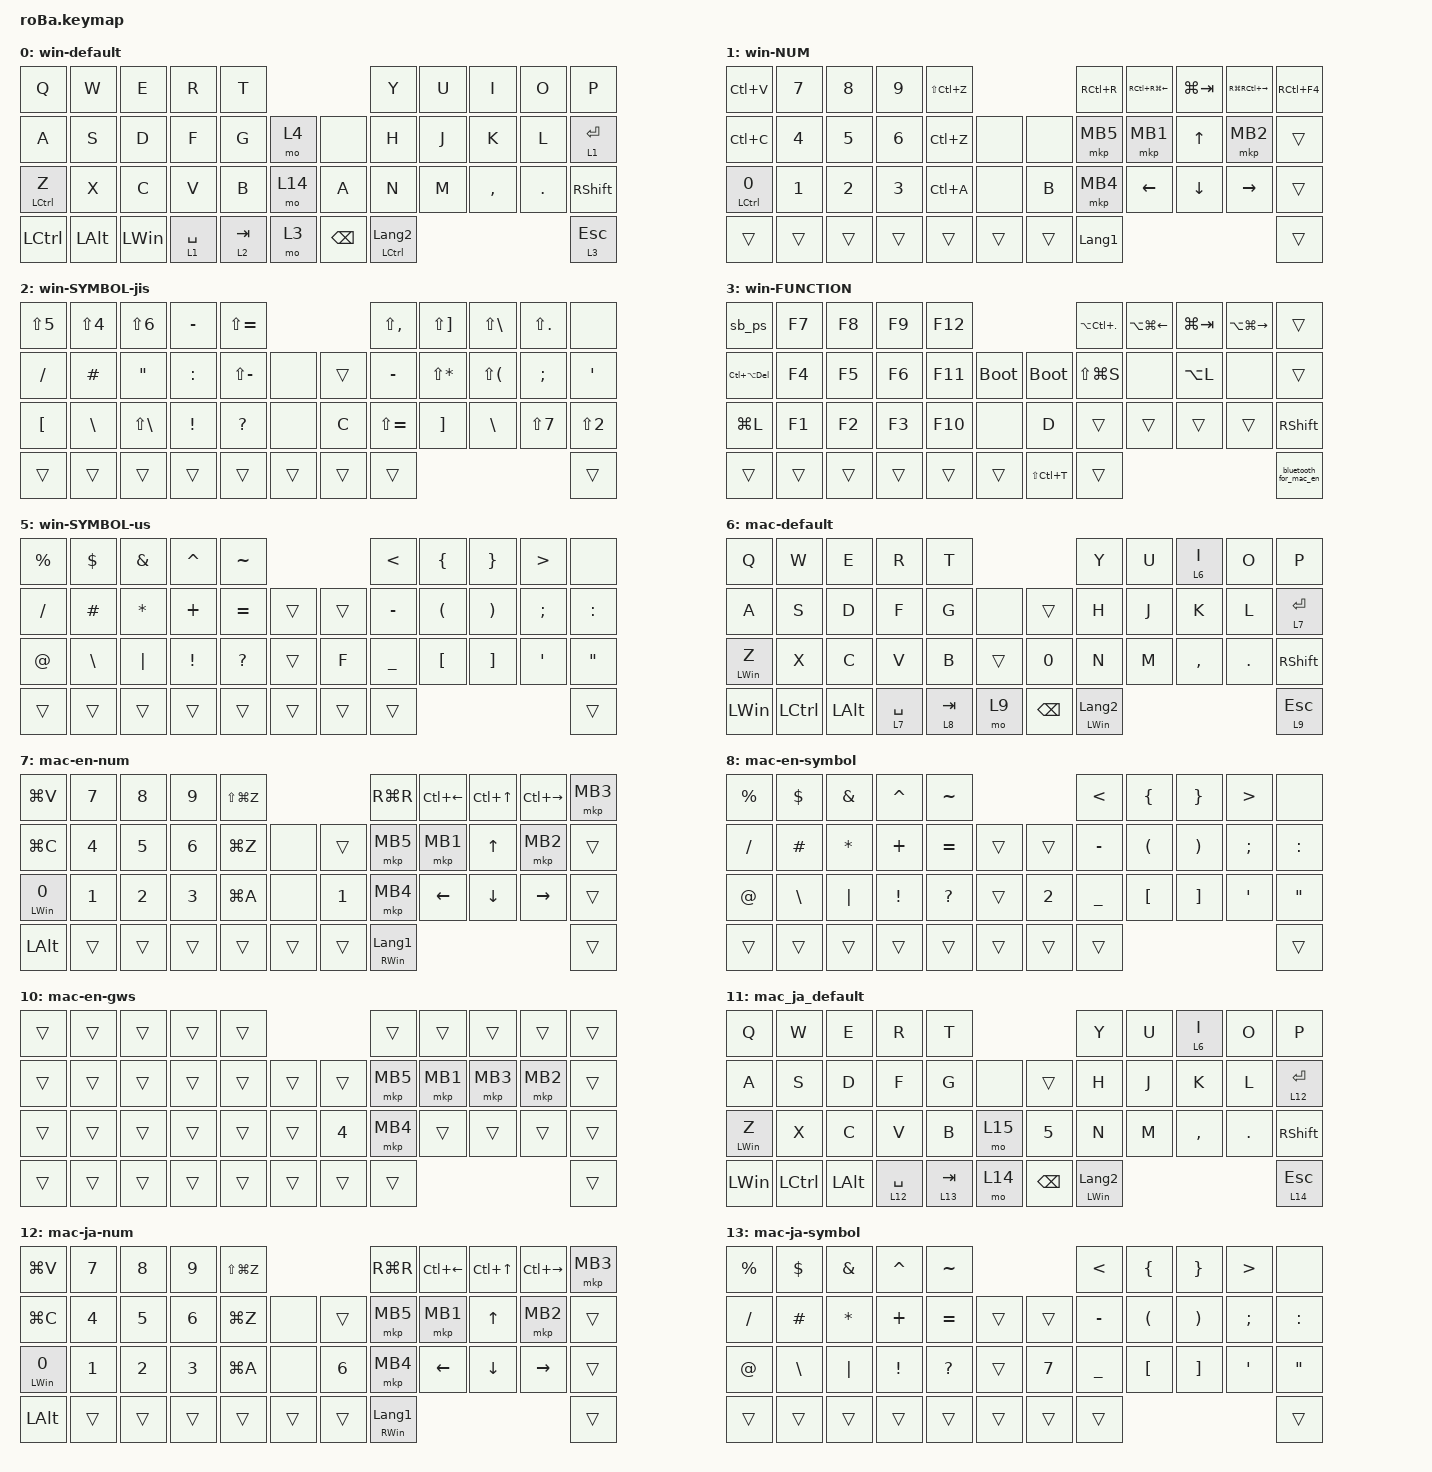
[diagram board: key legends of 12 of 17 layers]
#include <behaviors.dtsi>
#include <dt-bindings/zmk/bt.h>
#include <dt-bindings/zmk/keys.h>
#include <dt-bindings/zmk/pointing.h>

#define MOUSE 4
#define SCROLL 11
#define NUM 6

&mt {
    flavor = "balanced";
    quick-tap-ms = <0>;
};

/ {
    combos {
        compatible = "zmk,combos";

        tab {
            bindings = <&kp TAB>;
            key-positions = <11 12>;
        };

        shift_tab {
            bindings = <&kp LS(TAB)>;
            key-positions = <12 13>;
        };

        muhennkann {
            bindings = <&to_layer_0 INT_MUHENKAN>;
            key-positions = <11 10>;
        };

        double_quotation {
            bindings = <&kp DOUBLE_QUOTES>;
            key-positions = <20 21>;
        };

        eq {
            bindings = <&kp EQUAL>;
            key-positions = <24 25>;
        };
    };

    macros {
        to_layer_0: to_layer_0 {
            compatible = "zmk,behavior-macro-one-param";
            #binding-cells = <1>;
            bindings = <&to 6 &macro_param_1to1 &kp MACRO_PLACEHOLDER>;
            label = "TO_LAYER_0";
        };

        bluetooth_for_win: bluetooth_for_win {
            compatible = "zmk,behavior-macro";
            #binding-cells = <0>;
            bindings = <&bt BT_SEL 0>, <&macro_wait_time 100>, <&to 0>;

            label = "BLUETOOTH_FOR_WIN";
        };

        bluetooth_for_mac_en: bluetooth_for_mac {
            compatible = "zmk,behavior-macro";
            #binding-cells = <0>;
            bindings = <&bt BT_SEL 1>, <&macro_wait_time 100>, <&to 11>;

            label = "BLUETOOTH_FOR_MAC";
        };

        sb_ps: win_ps {
            compatible = "zmk,behavior-macro";
            #binding-cells = <0>;
            bindings = <&none &kp LS(B) &kp N5 &kp E &kp D &kp E &kp N6 &kp N4 &kp D &kp D &kp C>;
            label = "WIN_PS";
        };

        win_gslide_group: win_gslide_group {
            compatible = "zmk,behavior-macro";
            #binding-cells = <0>;
            bindings = <&sk LCTRL &kp LA(G)>;
            label = "WIN_GSLIDE_GROUP";
        };

        bluetooth_for_ja_mac: bluetooth_for_ja_mac {
            compatible = "zmk,behavior-macro";
            #binding-cells = <0>;
            bindings = <&bt BT_SEL 2>, <&macro_wait_time 100>, <&to 11>;

            label = "BLUETOOTH_FOR_JA_MAC";
        };

        gslide_group_mac: gslide_group_mac {
            compatible = "zmk,behavior-macro";
            #binding-cells = <0>;
            bindings = <&kp LG(LA(G))>;
            label = "GSLIDE_GROUP_MAC";
        };

        gslide_ungroup_mac: gslide_ungroup_mac {
            compatible = "zmk,behavior-macro";
            #binding-cells = <0>;
            bindings = <&kp LG(LA(LS(G)))>;
            label = "GSLIDE_UNGROUP_MAC";
        };

        screenshot_mac: screenshot_mac {
            compatible = "zmk,behavior-macro";
            #binding-cells = <0>;
            bindings = <&kp LS(LG(NUMBER_4))>;
            label = "SCREENSHOT_MAC";
        };

        gdocs_h1_mac: gdocs_h1_mac {
            compatible = "zmk,behavior-macro";
            #binding-cells = <0>;
            bindings = <&kp LA(LG(NUMBER_1))>;
            label = "GDOCS_H1_MAC";
        };

        chrome_previous_browser_tab: previous_browser_mac {
            compatible = "zmk,behavior-macro";
            #binding-cells = <0>;
            bindings = <&kp LG(LS(T))>;
            label = "PREVIOUS_BROWSER_MAC";
        };

        gdocs_h2_mac: gdocs_h2_mac {
            compatible = "zmk,behavior-macro";
            #binding-cells = <0>;
            bindings = <&kp LA(LG(NUMBER_2))>;
            label = "GDOCS_H2_MAC";
        };

        gdocs_h3_mac: gdocs_h3_mac {
            compatible = "zmk,behavior-macro";
            #binding-cells = <0>;
            bindings = <&kp LA(LG(NUMBER_3))>;
            label = "GDOCS_H3_MAC";
        };

        gdocs_h4_mac: gdocs_h4_mac {
            compatible = "zmk,behavior-macro";
            #binding-cells = <0>;
            bindings = <&kp LA(LG(NUMBER_4))>;
            label = "GDOCS_H4_MAC";
        };

        gdocs_h5_mac: gdocs_h5_mac {
            compatible = "zmk,behavior-macro";
            #binding-cells = <0>;
            bindings = <&kp LA(LG(N5))>;
            label = "GDOCS_H5_MAC";
        };

        gws_comment_mac: gws_comment_mac {
            compatible = "zmk,behavior-macro";
            #binding-cells = <0>;
            bindings = <&kp LG(LA(M))>;
            label = "GWS_COMMENT_MAC";
        };
    };

    behaviors {
        lt_to_layer_0: lt_to_layer_0 {
            compatible = "zmk,behavior-hold-tap";
            label = "LAYER_TAP_TO_0";
            bindings = <&mo>, <&to_layer_0>;

            #binding-cells = <2>;
            tapping-term-ms = <200>;
        };
    };

    keymap {
        compatible = "zmk,keymap";

        win-default {
            bindings = <
&kp Q        &kp W         &kp E         &kp R        &kp T                                 &kp Y                 &kp U  &kp I      &kp O    &kp P
&kp A        &kp S         &kp D         &kp F        &kp G      &mo 4       &none          &kp H                 &kp J  &kp K      &kp L    &lt 1 ENTER
&mt LCTRL Z  &kp X         &kp C         &kp V        &kp B      &mo 14      &kp A          &kp N                 &kp M  &kp COMMA  &kp DOT  &kp RIGHT_SHIFT
&kp LCTRL    &kp LEFT_ALT  &kp LEFT_WIN  &lt 1 SPACE  &lt 2 TAB  &mo 3       &kp BACKSPACE  &mt LCTRL LANGUAGE_2                             &lt 3 ESCAPE
            >;

            sensor-bindings = <&inc_dec_kp PG_UP PAGE_DOWN>;
        };

        win-NUM {
            bindings = <
&kp LC(V)     &kp N7        &kp N8        &kp N9        &kp LS(LC(Z))                      &kp RC(R)       &kp RC(RG(LEFT))  &kp LG(TAB)     &kp RG(RC(RIGHT_ARROW))  &kp RC(F4)
&kp LC(C)     &kp NUMBER_4  &kp N5        &kp NUMBER_6  &kp LC(Z)      &none       &none   &mkp MB5        &mkp MB1          &kp UP_ARROW    &mkp MB2                 &trans
&mt LCTRL N0  &kp NUMBER_1  &kp NUMBER_2  &kp NUMBER_3  &kp LC(A)      &none       &kp B   &mkp MB4        &kp LEFT_ARROW    &kp DOWN_ARROW  &kp RIGHT_ARROW          &trans
&trans        &trans        &trans        &trans        &trans         &trans      &trans  &kp LANGUAGE_1                                                             &trans
            >;
        };

        win-SYMBOL-jis {
            bindings = <
&kp LS(N5)        &kp LS(NUMBER_4)  &kp LS(NUMBER_6)   &kp MINUS  &kp LS(EQUAL)                      &kp LS(COMMA)  &kp LS(RIGHT_BRACKET)  &kp LS(BACKSLASH)         &kp LS(PERIOD)  &none
&kp SLASH         &kp HASH          &kp DOUBLE_QUOTES  &kp COLON  &kp LS(MINUS)  &none       &trans  &kp MINUS      &kp LS(ASTERISK)       &kp LS(LEFT_PARENTHESIS)  &kp SEMICOLON   &kp SINGLE_QUOTE
&kp LEFT_BRACKET  &kp BACKSLASH     &kp LS(BACKSLASH)  &kp EXCL   &kp QUESTION   &none       &kp C   &kp LS(EQUAL)  &kp RIGHT_BRACKET      &kp BACKSLASH             &kp LS(N7)      &kp LS(NUMBER_2)
&trans            &trans            &trans             &trans     &trans         &trans      &trans  &trans                                                                          &trans
            >;
        };

        win-FUNCTION {
            bindings = <
&sb_ps              &kp F7  &kp F8  &kp F9  &kp F12                                  &kp LA(LC(PERIOD))  &kp LA(LG(LEFT_ARROW))  &kp LG(TAB)  &kp LA(LG(RIGHT_ARROW))  &trans
&kp LC(LA(DELETE))  &kp F4  &kp F5  &kp F6  &kp F11  &bootloader      &bootloader    &kp LS(LG(S))       &none                   &kp LA(L)    &none                    &trans
&kp LG(L)           &kp F1  &kp F2  &kp F3  &kp F10  &none            &kp D          &trans              &trans                  &trans       &trans                   &kp RSHIFT
&trans              &trans  &trans  &trans  &trans   &trans           &kp LS(LC(T))  &trans                                                                            &bluetooth_for_mac_en
            >;

            sensor-bindings = <&inc_dec_kp LC(PAGE_UP) LC(PAGE_DOWN)>;
        };

        win-GWS {
            bindings = <
&trans  &trans                &trans                &trans                &trans                                    &none       &none              &none              &none              &none
&trans  &kp LA(LC(NUMBER_4))  &kp LA(LC(N5))        &trans                &trans  &none       &none                 &kp LC(N0)  &win_gslide_group  &trans             &kp LC(LA(LS(G)))  &none
&trans  &kp LA(LC(NUMBER_1))  &kp LC(LA(NUMBER_2))  &kp LA(LC(NUMBER_3))  &trans  &none       &kp E                 &none       &none              &kp LC(BACKSLASH)  &none              &none
&trans  &trans                &trans                &trans                &trans  &trans      &kp LS(LA(NUMBER_5))  &trans                                                               &none
            >;
        };

        win-SYMBOL-us {
            bindings = <
&kp PERCENT  &kp DOLLAR     &kp AMPERSAND  &kp CARET  &kp TILDE                         &kp LESS_THAN  &kp LBRC  &kp RIGHT_BRACE        &kp GREATER_THAN  &none
&kp SLASH    &kp POUND      &kp ASTRK      &kp PLUS   &kp EQUAL     &trans      &trans  &kp MINUS      &kp LPAR  &kp RIGHT_PARENTHESIS  &kp SEMICOLON     &kp COLON
&kp AT       &kp BACKSLASH  &kp PIPE       &kp EXCL   &kp QUESTION  &trans      &kp F   &kp UNDER      &kp LBKT  &kp RIGHT_BRACKET      &kp SQT           &kp DOUBLE_QUOTES
&trans       &trans         &trans         &trans     &trans        &trans      &trans  &trans                                                            &trans
            >;
        };

        mac-default {
            bindings = <
&kp Q           &kp W      &kp E         &kp R        &kp T                                 &kp Y                    &kp U  &lt 6 I    &kp O    &kp P
&kp A           &kp S      &kp D         &kp F        &kp G      &none       &trans         &kp H                    &kp J  &kp K      &kp L    &lt 7 ENTER
&mt LEFT_WIN Z  &kp X      &kp C         &kp V        &kp B      &trans      &kp N0         &kp N                    &kp M  &kp COMMA  &kp DOT  &kp RIGHT_SHIFT
&kp LEFT_WIN    &kp LCTRL  &kp LEFT_ALT  &lt 7 SPACE  &lt 8 TAB  &mo 9       &kp BACKSPACE  &mt LEFT_WIN LANGUAGE_2                             &lt 9 ESCAPE
            >;

            sensor-bindings = <&inc_dec_kp PG_UP PAGE_DOWN>;
        };

        mac-en-num {
            bindings = <
&kp LG(V)        &kp N7        &kp N8        &kp N9        &kp LS(LG(Z))                            &kp RG(R)                 &kp LC(LEFT_ARROW)  &kp LC(UP_ARROW)  &kp LC(RIGHT_ARROW)  &mkp MB3
&kp LG(C)        &kp NUMBER_4  &kp N5        &kp NUMBER_6  &kp LG(Z)      &none       &trans        &mkp MB5                  &mkp MB1            &kp UP_ARROW      &mkp MB2             &trans
&mt LEFT_WIN N0  &kp NUMBER_1  &kp NUMBER_2  &kp NUMBER_3  &kp LG(A)      &none       &kp NUMBER_1  &mkp MB4                  &kp LEFT_ARROW      &kp DOWN_ARROW    &kp RIGHT_ARROW      &trans
&kp LEFT_ALT     &trans        &trans        &trans        &trans         &trans      &trans        &mt RIGHT_WIN LANGUAGE_1                                                             &trans
            >;
        };

        mac-en-symbol {
            bindings = <
&kp PERCENT  &kp DOLLAR     &kp AMPERSAND  &kp CARET  &kp TILDE                               &kp LESS_THAN  &kp LEFT_BRACE        &kp RIGHT_BRACE        &kp GREATER_THAN  &none
&kp SLASH    &kp POUND      &kp ASTRK      &kp PLUS   &kp EQUAL     &trans      &trans        &kp MINUS      &kp LEFT_PARENTHESIS  &kp RIGHT_PARENTHESIS  &kp SEMICOLON     &kp COLON
&kp AT       &kp BACKSLASH  &kp PIPE       &kp EXCL   &kp QUESTION  &trans      &kp NUMBER_2  &kp UNDER      &kp LEFT_BRACKET      &kp RIGHT_BRACKET      &kp SQT           &kp DOUBLE_QUOTES
&trans       &trans         &trans         &trans     &trans        &trans      &trans        &trans                                                                        &trans
            >;
        };

        mac-en-function {
            bindings = <
&trans                &kp F7  &kp F8  &kp F9  &kp F12                                  &kp LA(LG(LEFT_ARROW))  &kp LC(LA(LEFT_ARROW))  &kp LA(LC(UP_ARROW))  &kp LC(LA(RIGHT_ARROW))  &kp LA(LC(RIGHT_ARROW))
&kp LS(LG(NUMBER_4))  &kp F4  &kp F5  &kp F6  &kp F11  &bootloader      &bootloader    &kp LS(LG(NUMBER_4))    &kp LA(LG(G))           &kp LA(SPACE)         &kp LS(LA(LG(G)))        &trans
&kp LCTRL             &kp F1  &kp F2  &kp F3  &kp F10  &trans           &kp NUMBER_3   &trans                  &trans                  &trans                &trans                   &trans
&trans                &trans  &trans  &trans  &trans   &trans           &kp LG(LS(T))  &trans                                                                                         &bluetooth_for_ja_mac
            >;

            sensor-bindings = <&inc_dec_kp LC(PAGE_UP) LC(PAGE_DOWN)>;
        };

        mac-en-gws {
            bindings = <
&trans  &trans  &trans  &trans  &trans                            &trans    &trans    &trans    &trans    &trans
&trans  &trans  &trans  &trans  &trans  &trans      &trans        &mkp MB5  &mkp MB1  &mkp MB3  &mkp MB2  &trans
&trans  &trans  &trans  &trans  &trans  &trans      &kp NUMBER_4  &mkp MB4  &trans    &trans    &trans    &trans
&trans  &trans  &trans  &trans  &trans  &trans      &trans        &trans                                  &trans
            >;
        };

        mac_ja_default {
            bindings = <
&kp Q           &kp W      &kp E         &kp R         &kp T                                  &kp Y                    &kp U  &lt 6 I    &kp O    &kp P
&kp A           &kp S      &kp D         &kp F         &kp G       &none       &trans         &kp H                    &kp J  &kp K      &kp L    &lt 12 ENTER
&mt LEFT_WIN Z  &kp X      &kp C         &kp V         &kp B       &mo 15      &kp NUMBER_5   &kp N                    &kp M  &kp COMMA  &kp DOT  &kp RIGHT_SHIFT
&kp LEFT_WIN    &kp LCTRL  &kp LEFT_ALT  &lt 12 SPACE  &lt 13 TAB  &mo 14      &kp BACKSPACE  &mt LEFT_WIN LANGUAGE_2                             &lt 14 ESCAPE
            >;

            sensor-bindings = <&inc_dec_kp PG_UP PAGE_DOWN>;
        };

        mac-ja-num {
            bindings = <
&kp LG(V)        &kp N7        &kp N8        &kp N9        &kp LS(LG(Z))                            &kp RG(R)                 &kp LC(LEFT_ARROW)  &kp LC(UP_ARROW)  &kp LC(RIGHT_ARROW)  &mkp MB3
&kp LG(C)        &kp NUMBER_4  &kp N5        &kp NUMBER_6  &kp LG(Z)      &none       &trans        &mkp MB5                  &mkp MB1            &kp UP_ARROW      &mkp MB2             &trans
&mt LEFT_WIN N0  &kp NUMBER_1  &kp NUMBER_2  &kp NUMBER_3  &kp LG(A)      &none       &kp NUMBER_6  &mkp MB4                  &kp LEFT_ARROW      &kp DOWN_ARROW    &kp RIGHT_ARROW      &trans
&kp LEFT_ALT     &trans        &trans        &trans        &trans         &trans      &trans        &mt RIGHT_WIN LANGUAGE_1                                                             &trans
            >;
        };

        mac-ja-symbol {
            bindings = <
&kp PERCENT  &kp DOLLAR     &kp AMPERSAND  &kp CARET  &kp TILDE                               &kp LESS_THAN  &kp LEFT_BRACE        &kp RIGHT_BRACE        &kp GREATER_THAN  &none
&kp SLASH    &kp POUND      &kp ASTRK      &kp PLUS   &kp EQUAL     &trans      &trans        &kp MINUS      &kp LEFT_PARENTHESIS  &kp RIGHT_PARENTHESIS  &kp SEMICOLON     &kp COLON
&kp AT       &kp BACKSLASH  &kp PIPE       &kp EXCL   &kp QUESTION  &trans      &kp NUMBER_7  &kp UNDER      &kp LEFT_BRACKET      &kp RIGHT_BRACKET      &kp SQT           &kp DOUBLE_QUOTES
&trans       &trans         &trans         &trans     &trans        &trans      &trans        &trans                                                                        &trans
            >;
        };

        mac-ja-function {
            bindings = <
&sb_ps           &kp F7  &kp F8  &kp F9  &kp F12                                                 &kp LA(LG(LEFT_ARROW))  &kp LC(LA(D))  &kp LA(LC(F))  &kp LC(LA(G))  &kp LA(LC(RIGHT_ARROW))
&screenshot_mac  &kp F4  &kp F5  &kp F6  &kp F11  &bootloader      &bootloader                   &trans                  &trans         &kp LA(SPACE)  &trans         &trans
&kp LCTRL        &kp F1  &kp F2  &kp F3  &kp F10  &trans           &kp NUMBER_8                  &trans                  &trans         &trans         &trans         &trans
&trans           &trans  &trans  &trans  &trans   &trans           &chrome_previous_browser_tab  &trans                                                               &bluetooth_for_win
            >;

            sensor-bindings = <&inc_dec_kp LC(PAGE_UP) LC(PAGE_DOWN)>;
        };

        mac-ja-gws {
            bindings = <
&trans  &trans         &trans         &trans         &trans                                    &none       &none              &none              &none                &none
&trans  &gdocs_h4_mac  &gdocs_h5_mac  &trans         &trans  &none       &none                 &kp LC(N0)  &gslide_group_mac  &trans             &gslide_ungroup_mac  &none
&trans  &gdocs_h1_mac  &gdocs_h2_mac  &gdocs_h3_mac  &trans  &none       &kp N9                &none       &gws_comment_mac   &kp LC(BACKSLASH)  &none                &none
&trans  &trans         &trans         &trans         &trans  &trans      &kp LS(LA(NUMBER_5))  &trans                                                                 &none
            >;
        };

        layer_10 {
            bindings = <
&trans  &trans  &trans  &trans  &trans                         &trans  &trans  &trans  &trans  &trans
&trans  &trans  &trans  &trans  &trans  &trans      &trans     &trans  &trans  &trans  &trans  &trans
&trans  &trans  &trans  &trans  &trans  &trans      &kp LS(X)  &trans  &trans  &none   &trans  &trans
&trans  &trans  &trans  &trans  &trans  &trans      &trans     &trans                          &trans
            >;
        };
    };
};
